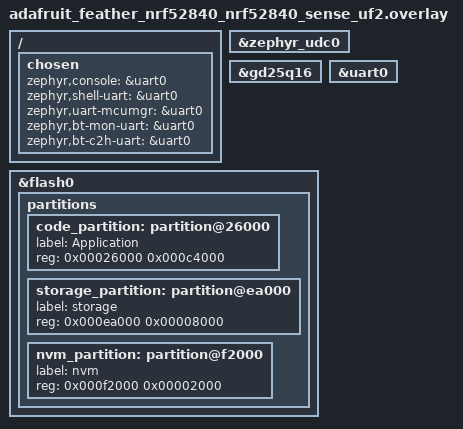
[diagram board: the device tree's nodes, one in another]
/ {
	chosen {
		zephyr,console = &uart0;
		zephyr,shell-uart = &uart0;
		zephyr,uart-mcumgr = &uart0;
		zephyr,bt-mon-uart = &uart0;
		zephyr,bt-c2h-uart = &uart0;
	};
};

&zephyr_udc0 {
	/delete-node/ board_cdc_acm_uart;
};


&gd25q16 {
	/delete-node/ partitions;
};

/delete-node/ &storage_partition;
/delete-node/ &code_partition;

&flash0 {
	partitions {
		code_partition: partition@26000 {
			label = "Application";
			reg = <0x00026000 0x000c4000>;
		};

		storage_partition: partition@ea000 {
			label = "storage";
			reg = <0x000ea000 0x00008000>;
		};

		nvm_partition: partition@f2000 {
			label = "nvm";
			reg = <0x000f2000 0x00002000>;
		};
	};
};

&uart0 {
    status = "okay";
};

#include "../app.overlay"
